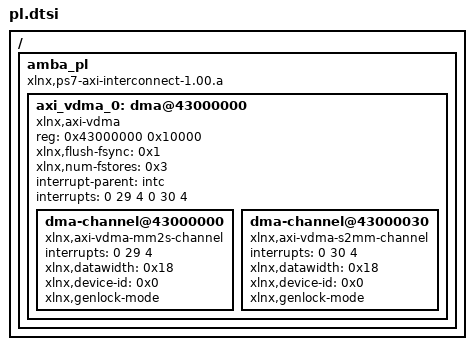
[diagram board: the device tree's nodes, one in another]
/*
 * CAUTION: This file is automatically generated by Xilinx.
 * Version:  
 * Today is: Fri Apr 22 22:12:07 2016
*/


/ {
	amba_pl: amba_pl {
		#address-cells = <1>;
		#size-cells = <1>;
		compatible = "xlnx,ps7-axi-interconnect-1.00.a", "simple-bus";
		ranges ;
		axi_vdma_0: dma@43000000 {
			#dma-cells = <1>;
			compatible = "xlnx,axi-vdma";
			reg = <0x43000000 0x10000>;
			xlnx,flush-fsync = <0x1>;
			xlnx,num-fstores = <0x3>;
			interrupt-parent = <&intc>;
			interrupts = <0 29 4 0 30 4>;
			dma-channel@43000000 {
				compatible = "xlnx,axi-vdma-mm2s-channel";
				interrupts = <0 29 4>;
				xlnx,datawidth = <0x18>;
				xlnx,device-id = <0x0>;
				xlnx,genlock-mode ;
			};
			dma-channel@43000030 {
				compatible = "xlnx,axi-vdma-s2mm-channel";
				interrupts = <0 30 4>;
				xlnx,datawidth = <0x18>;
				xlnx,device-id = <0x0>;
				xlnx,genlock-mode ;
			};
		};
	};
};
